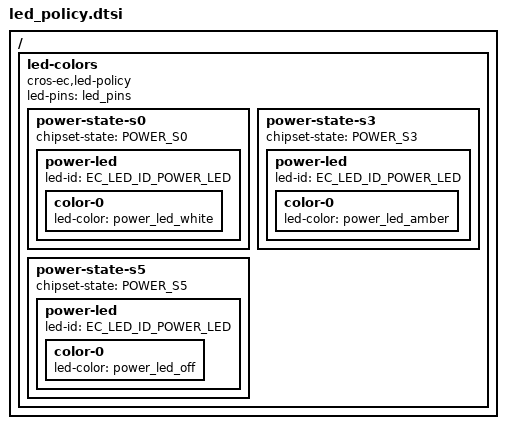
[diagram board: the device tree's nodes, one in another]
/ {
	led-colors {
		compatible = "cros-ec,led-policy";
		led-pins = <&led_pins>;

		power-state-s0 {
			chipset-state = "POWER_S0";

			power-led {
				led-id = "EC_LED_ID_POWER_LED";

				color-0 {
					led-color = <&power_led_white>;
				};
			};
		};

		power-state-s3 {
			chipset-state = "POWER_S3";

			power-led {
				led-id = "EC_LED_ID_POWER_LED";

				color-0 {
					led-color = <&power_led_amber>;
				};
			};
		};


		power-state-s5 {
			chipset-state = "POWER_S5";

			power-led {
				led-id = "EC_LED_ID_POWER_LED";

				color-0 {
					led-color = <&power_led_off>;
				};
			};
		};
	};
};
